# EFR32MR21A020F512IM32 register map
Vendor: Silicon Labs; Series: EFR32; File version: D
Registers are 32-bit, read-write, reset 0x0 unless marked. A register's access mark holds for its fields unless they carry their own. Offsets are from the block's base; [hi:lo] are bit positions; {n}, {i} and the like mark numbered series; 'fields as' and 'values as' point back to an identical list.

## RADIOAES_NS — RADIOAES_NS Registers
Base 0x54000000
Same registers: RADIOAES_S 0x44000000
0x00 FETCHADDR — Fetcher: Start address of data block
  [31:0] ADDR — Start address of data block
0x04 FETCHDESCR — Fetcher: Descriptor address (Should be renamed to match Barco doc after PG)
  [31:0] DESCR — Descriptor address
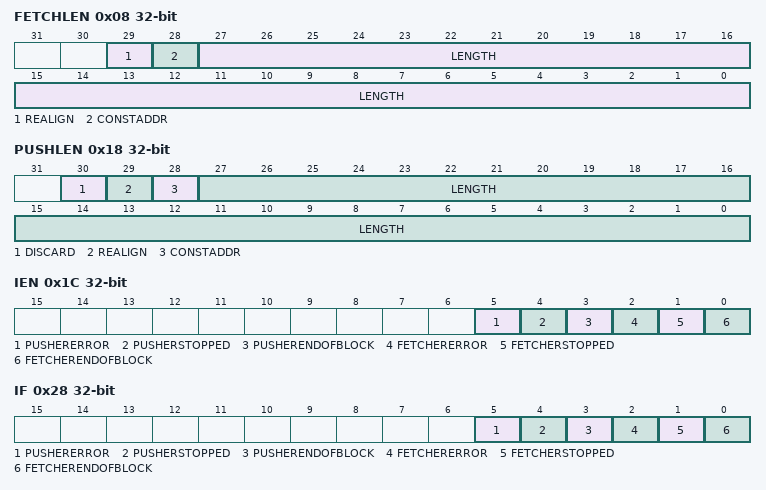
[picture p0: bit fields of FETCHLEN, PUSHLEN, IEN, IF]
0x08 FETCHLEN — Fetcher: Length of data block
  [29] REALIGN — Realign lengh
  [28] CONSTADDR — Constant address
  [27:0] LENGTH — Length of data block
0x0C FETCHTAG — Fetcher: User tag
  [31:0] TAG — User tag
0x10 PUSHADDR — Pusher: Start address of data block
  [31:0] ADDR — Start address of data block
0x14 PUSHDESCR — Pusher: Descriptor address (Should be renamed to match Barco doc after PG)
  [31:0] DESCR — Descriptor address
0x18 PUSHLEN — Pusher: Length of data block
  [30] DISCARD — Discard data
  [29] REALIGN — Realign length
  [28] CONSTADDR — Constant address
  [27:0] LENGTH — Start address of data block
0x1C IEN — Interrupt enable
  [5] PUSHERERROR — Error interrupt enable
  [4] PUSHERSTOPPED — Stopped interrupt enable
  [3] PUSHERENDOFBLOCK — End of block interrupt enable
  [2] FETCHERERROR — Error interrupt enable
  [1] FETCHERSTOPPED — Stopped interrupt enable
  [0] FETCHERENDOFBLOCK — End of block interrupt enable
0x28 IF ro — Interrupt flag register
  [5] PUSHERERROR — Error interrupt flag
  [4] PUSHERSTOPPED — Stopped interrupt flag
  [3] PUSHERENDOFBLOCK — End of block interrupt flag
  [2] FETCHERERROR — Error interrupt flag
  [1] FETCHERSTOPPED — Stopped interrupt flag
  [0] FETCHERENDOFBLOCK — End of block interrupt flag
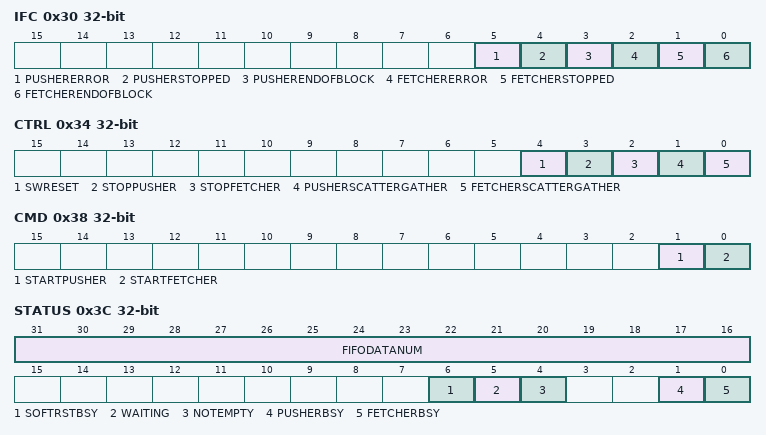
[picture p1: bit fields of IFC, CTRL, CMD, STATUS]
0x30 IFC wo — Writing a '1' clears the interrupt status. Writing a '0' has no effect.
  [5] PUSHERERROR — New BitField
  [4] PUSHERSTOPPED — New BitField
  [3] PUSHERENDOFBLOCK — New BitField
  [2] FETCHERERROR — Error interrupt flag clear
  [1] FETCHERSTOPPED — Stopped interrupt flag clear
  [0] FETCHERENDOFBLOCK — End of block interrupt flag clear
0x34 CTRL — Control register, called CONFIG in Barco datasheet.
  [4] SWRESET — Software reset
  [3] STOPPUSHER
  [2] STOPFETCHER
  [1] PUSHERSCATTERGATHER
  [0] FETCHERSCATTERGATHER
0x38 CMD wo — Command register for starting the fetcher and pusher
  [1] STARTPUSHER — Start push
  [0] STARTFETCHER — Start fetch
0x3C STATUS ro
  [31:16] FIFODATANUM — Number of data in output FIFO
  [6] SOFTRSTBSY — Software reset busy
  [5] WAITING — Pusher waiting for FIFO
  [4] NOTEMPTY — Not empty flag from input FIFO (fetcher)
  [1] PUSHERBSY — Pusher busy
  [0] FETCHERBSY — Fetcher busy

## SEMAILBOX_NS_HOST — SEMAILBOX_NS_HOST Registers
Base 0x5C000000
Same registers: SEMAILBOX_S_HOST 0x4C000000
{0x0+4i} DATA{i} (i=0..15) — RX/TX FIFO DATA
  [31:0] DATA — FIFO Data
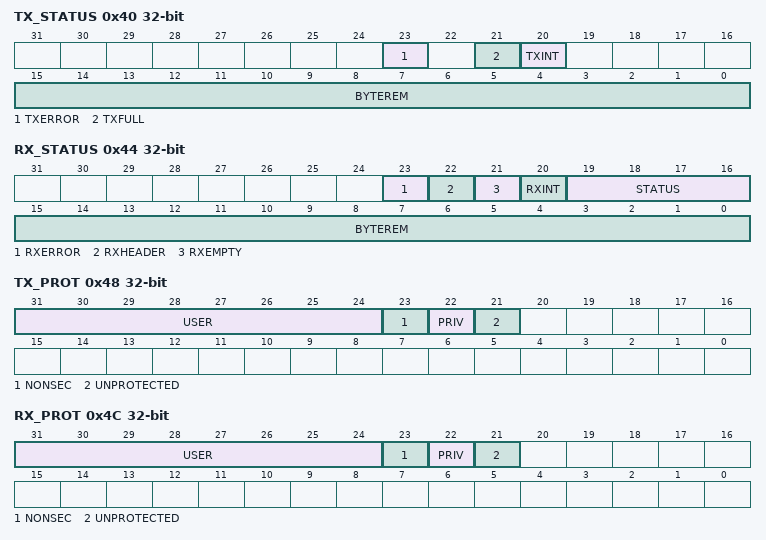
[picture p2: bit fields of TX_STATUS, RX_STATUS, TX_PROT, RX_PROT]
0x40 TX_STATUS ro
  [23] TXERROR — TX Error Flag
  [21] TXFULL — TX FIFO Full
  [20] TXINT — Interrupt Status
  [15:0] BYTEREM — Bytes Remaining
0x44 RX_STATUS ro
  [23] RXERROR — RX Error Flag
  [22] RXHEADER
  [21] RXEMPTY — RX FIFO Empty
  [20] RXINT — Interrupt Status
  [19:16] STATUS — Message Status
  [15:0] BYTEREM — Bytes Remaining
0x48 TX_PROT ro
  [31:24] USER — User Bits
  [23] NONSEC — Non-Secure Access
  [22] PRIV — Privileged Access
  [21] UNPROTECTED
0x4C RX_PROT ro
  fields as TX_PROT
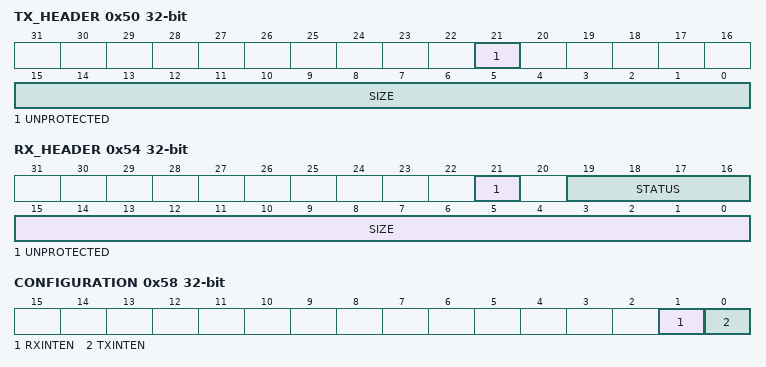
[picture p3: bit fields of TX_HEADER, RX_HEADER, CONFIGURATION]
0x50 TX_HEADER wo
  [21] UNPROTECTED
  [15:0] SIZE — Command Size
0x54 RX_HEADER ro
  [21] UNPROTECTED
  [19:16] STATUS — Command Status
  [15:0] SIZE
0x58 CONFIGURATION
  [1] RXINTEN — RX Interrupt Enable
  [0] TXINTEN — TX Interrupt Enable

## SYSCFG_NS — SYSCFG_NS Registers
Base 0x5007C000
Same registers: SYSCFG_S 0x4007C000
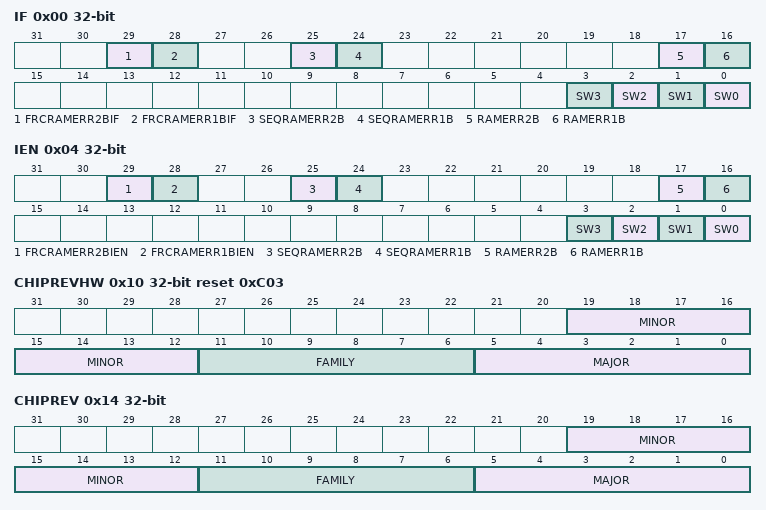
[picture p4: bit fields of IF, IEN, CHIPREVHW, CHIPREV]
0x00 IF
  [29] FRCRAMERR2BIF — FRCRAM 2-bit ECC Error Interrupt flag
  [28] FRCRAMERR1BIF — FRCRAM 1-bit ECC Error Interrupt flag
  [25] SEQRAMERR2B — SEQRAM 2-bit ECC Error Interrupt flag
  [24] SEQRAMERR1B — SEQRAM 1-bit ECC Error Interrupt flag
  [17] RAMERR2B — RAM 2-bit ECC Error Interrupt flag
  [16] RAMERR1B — RAM 1-bit ECC Error Interrupt flag
  [n] SW{n} (n=0..3) — Software Interrupt {n}
0x04 IEN
  [29] FRCRAMERR2BIEN — FRCRAM 2-bit ECC Error Interrupt enable
  [28] FRCRAMERR1BIEN — FRCRAM 1-bit ECC Error Interrupt enable
  [25] SEQRAMERR2B — SEQRAM 2-bit ECC Error Interrupt enable
  [24] SEQRAMERR1B — SEQRAM 1-bit ECC Error Interrupt enable
  [17] RAMERR2B — RAM 2-bit ECC Error Interrupt enable
  [16] RAMERR1B — RAM 1-bit ECC Error Interrupt enable
  [n] SW{n} (n=0..3) — Software Interrupt {n}
0x10 CHIPREVHW reset 0xC03
  [19:12] MINOR — Chip Rev Minor value
  [11:6] FAMILY — Chip Family value
  [5:0] MAJOR — Chip Rev Major value
0x14 CHIPREV
  [19:12] MINOR — Chip Rev Minor value
  [11:6] FAMILY — Chip Family value
    48=MG21 (Product is in MG21 family); 49=BG21 (Product is in BG21 family); 51=MR21 (Product is in MR21 family)
  [5:0] MAJOR — Chip Rev Major value
0x24 CFGSYSTIC
  [0] SYSTICEXTCLKEN — SysTick External Clock Enable
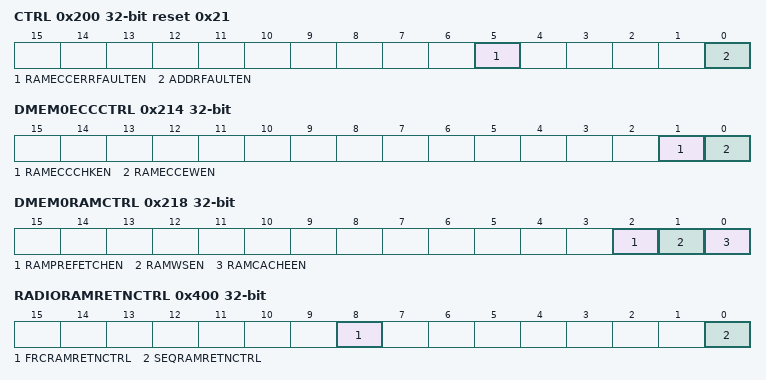
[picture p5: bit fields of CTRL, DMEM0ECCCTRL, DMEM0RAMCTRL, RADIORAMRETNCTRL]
0x200 CTRL reset 0x21
  [5] RAMECCERRFAULTEN — Two bit ECC Error Bus Fault Response Enable
  [0] ADDRFAULTEN — Invalid Address Bus Fault Response Enable
0x208 DMEM0RETNCTRL
  [4:0] RAMRETNCTRL — DMEM0 blockset retention control
    0=ALLON (None of the RAM blocks powered down); 16=BLK5 (Power down RAM block 5 (address range 0x20014000-0x20017FFF)); 24=BLK4TO5 (Power down RAM blocks 4 and above (address range 0x20010000-0x20017FFF)); 28=BLK3TO5 (Power down RAM blocks 3 and above (address range 0x2000C000-0x20017FFF)); 30=BLK2TO5 (Power down RAM blocks 2 and above (address range 0x20008000-0x20017FFF)); 31=BLK1TO5 (Power down RAM blocks 1 and above (address range 0x20004000-0x20017FFF))
0x210 DMEM0ECCADDR ro
  [31:0] DMEM0ECCADDR — DMEM0 RAM ECC Error Address
0x214 DMEM0ECCCTRL
  [1] RAMECCCHKEN — RAM ECC Check Enable
  [0] RAMECCEWEN — RAM ECC Write Enable
0x218 DMEM0RAMCTRL
  [2] RAMPREFETCHEN — RAM Prfetch Enable
  [1] RAMWSEN — RAM WAIT STATE Enable
  [0] RAMCACHEEN — RAM CACHE Enable
0x400 RADIORAMRETNCTRL
  [8] FRCRAMRETNCTRL — FRCRAM Memory Shutdown Control Register
    0=ALLON (FRCRAM not powered down); 1=FRCBLK (Power down FRCRAM (address range 0x50002000-0x50002FFF))
  [0] SEQRAMRETNCTRL — SEQRAM Memory Shutdown Control Register
    0=ALLON (SEQRAM not powered down); 1=SEQBLK (Power down SEQRAM (address range 0x50000000-0x50001FFF))
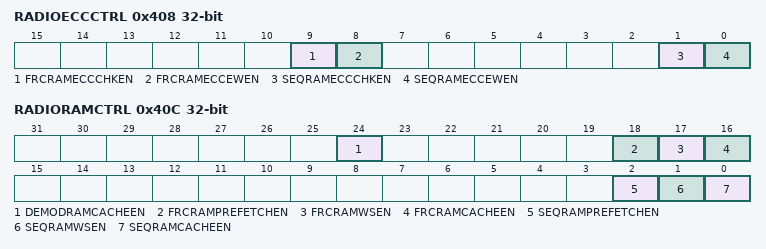
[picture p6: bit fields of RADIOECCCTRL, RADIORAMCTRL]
0x408 RADIOECCCTRL
  [9] FRCRAMECCCHKEN — FRCRAM ECC Check Enable
  [8] FRCRAMECCEWEN — FRCRAM ECC Write Enable
  [1] SEQRAMECCCHKEN — SEQRAM ECC Check Enable
  [0] SEQRAMECCEWEN — SEQRAM ECC Write Enable
0x40C RADIORAMCTRL
  [24] DEMODRAMCACHEEN — DEMODRAM CACHE Enable
  [18] FRCRAMPREFETCHEN — FRCRAM Prfetch Enable
  [17] FRCRAMWSEN — FRCRAM WAIT STATE Enable
  [16] FRCRAMCACHEEN — FRCRAM CACHE Enable
  [2] SEQRAMPREFETCHEN — SEQRAM Prfetch Enable
  [1] SEQRAMWSEN — SEQRAM WAIT STATE Enable
  [0] SEQRAMCACHEEN — SEQRAM CACHE Enable
0x410 SEQRAMECCADDR ro
  [31:0] SEQRAMECCADDR — SEQRAM ECC Error Address
0x414 FRCRAMECCADDR ro
  [31:0] FRCRAMECCADDR — FRCRAM ECC Error Address
